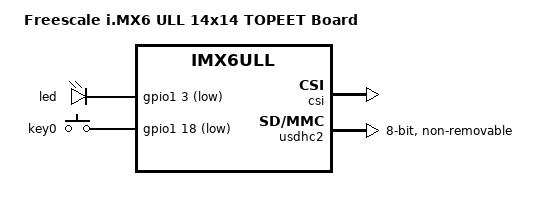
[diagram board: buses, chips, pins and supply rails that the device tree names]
// SPDX-License-Identifier: (GPL-2.0 OR MIT)
//
// Copyright (C) 2016 Freescale Semiconductor, Inc.

/dts-v1/;

#include "imx6ull.dtsi"
#include "imx6ul-14x14-topeet.dtsi"

/ {
	model = "Freescale i.MX6 ULL 14x14 TOPEET Board";
	compatible = "fsl,imx6ull-14x14-topeet", "fsl,imx6ull";

	leds {
		compatible = "gpio-leds";
		pinctrl-0 = <&pinctrl_leds>;
		led {
			label = "led";
			gpios = <&gpio1 3 GPIO_ACTIVE_LOW>;
			linux,default-trigger = "heartbeat";
			default-state = "on";
		};
	};

	keys {
		compatible = "gpio-keys";
		pinctrl-0 = <&pinctrl_keys>;
		autorepeat;

		key0 {
			label = "key0";
			linux,code = <KEY_ENTER>;
			gpios = <&gpio1 18 GPIO_ACTIVE_LOW>;
		};
	};
};

&clks {
	assigned-clocks = <&clks IMX6UL_CLK_PLL3_PFD2>,
			  <&clks IMX6UL_CLK_PLL4_AUDIO_DIV>;
	assigned-clock-rates = <320000000>, <786432000>;
};

&csi {
	status = "okay";
};

&usdhc2 {
	pinctrl-names = "default", "state_100mhz", "state_200mhz";
	pinctrl-0 = <&pinctrl_usdhc2_8bit>;
	pinctrl-1 = <&pinctrl_usdhc2_8bit_100mhz>;
	pinctrl-2 = <&pinctrl_usdhc2_8bit_200mhz>;
	bus-width = <8>;
	non-removable;
	status = "okay";
};

/delete-node/ &sim2;

&iomuxc {
	pinctrl_leds: ledsgrp {
		fsl,pins = <
			MX6UL_PAD_GPIO1_IO03__GPIO1_IO03		0xb0
		>;
	};
	pinctrl_keys: keysgrp {
		fsl,pins = <
			MX6UL_PAD_UART1_CTS_B__GPIO1_IO18       0xf080
		>;
	};
};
